# MCU_NAVSS0_UDMASS_UDMAP_TCHANRT register map
Vendor: Texas Instruments
Peripheral module from a debugger description file (folder am65x).
Registers are 32-bit, read-write, reset 0x0 unless marked. A register's access mark holds for its fields unless they carry their own. Offsets are as the file gives them; lines under a group give offsets from that group; [hi:lo] are bit positions; {n}, {i} and the like mark numbered series; 'fields as' and 'values as' point back to an identical list; <NAME> marks a mode.

## MCU_NAVSS0_UDMASS_UDMAP_TCHANRT
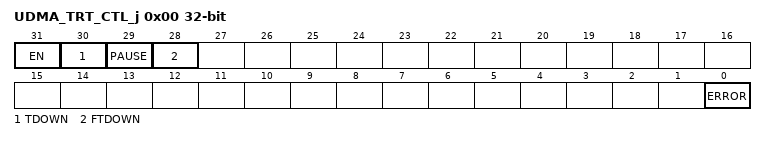
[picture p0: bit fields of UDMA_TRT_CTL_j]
0x00 UDMA_TRT_CTL_j access per field — The Tx Channel Realtime Control Register contains real-time control and status information for the Tx DMA channel. The fields in this register can safely be changed while the channel is in operation. Offset = 0h + (j * 1000h); where j = 0h to 97h for NAVSS0_UDMASS_UDMAP0_CFG_TCHANRT j = 0h to 2Fh for MCU_NAVSS0_UDMASS_UDMAP_TCHANRT
  [31] EN rw — This field enables or disables the channel. Disabling a channel halts operation on the channel after the current block transfer is completed. Disabling a channel in the middle of a packet transfer may result in underflow conditions in the attached application block and data loss. When a channel is disabled, the implementation may choose to reset all state for the channel. The pause bit should be asserted instead of clearing enable directly if the intent is to temporarily pause the channel. This field is encoded as follows: 0 = channel is disabled 1 = channel is enabled This field will be cleared by HW after a teardown is requested to indicate that the channel teardown is complete.
  [30] TDOWN rw — Channel teardown: Setting this bit will request the channel to be torn down. This field will remain set after a channel teardown is complete.
  [29] PAUSE rw — Channel pause: Setting this bit will cause the channel to pause processing immediately.
  [28] FTDOWN rw — Channel forced teardown: Setting this bit will cause the channel to stop waiting on trigger events. When this bit is set, the implementation may choose to bypass data transfers and event generation. This bit is a modifier to the normal tx_teardown and is intended to flush the channel to recover any descriptor or TR references which are currently being held by the UDMA-P even if the trigger source is no longer functioning. Uso fo this bit is considered a 'catastrophic' condition and it is assumed that SW will need to perform some re-initialization in the system to re-align events, data buffers, etc. This bit should be set in addition to the tx_teardown bit in order to cause a forced teardown. This field will remain set after a channel teardown is complete.
  [0] ERROR ro — Channel error: This bit will be set anytime an error has occurred on the channel. This bit is cleared when the channel is disabled and re-enabled.
0x08 UDMA_TRT_SWTRIG_j wo — The Software Trigger Register provides a mechanism by which software can directly trigger the channel in a secure way. This register is only used when the tx_chan_type is configured as a Third Party DMA channel. This register has no function when the channel is configured for packet mode transfers. A write to this register will cause an event to be sent to this channel. Offset = 8h + (j * 1000h); where j = 0h to 97h for NAVSS0_UDMASS_UDMAP0_CFG_TCHANRT j = 0h to 2Fh for MCU_NAVSS0_UDMASS_UDMAP_TCHANRT
  [0] TRIGGER — Trigger: writing this bit with a value of 1 will cause the trigger event to be sent to this channel
0x80 UDMA_TRT_STDATA_j_Y ro — The State Data Registers contain the current working state of the Tx DMA channel. These registers are provided so that the Host can determine the potential cause of an error or exception condition which was reported by the channel. These registers should not be accessed without reason while the UDMA-P is operating as accesses will cause performance to decrease as these MMRs are just providing a window into the actual state RAM Offset = 80h + (j * 1000h) + (y * 4h); where j = 0h to 97h, y = 0h to 1Fh for NAVSS0_UDMASS_UDMAP0_CFG_TCHANRT j = 0h to 2Fh, y = 0h to 1Fh for MCU_NAVSS0_UDMASS_UDMAP_TCHANRT
  [31:0] STATE_INFO — See Tx state mapping table
{0x200+4i} UDMA_TRT_PEER{i}_j (i=0..2) — This register provides access to the remote peer's realtime register at {0x400+i}. Offset = {4i+200}h + (j * 1000h); where j = 0h to 97h for NAVSS0_UDMASS_UDMAP0_CFG_TCHANRT j = 0h to 2Fh for MCU_NAVSS0_UDMASS_UDMAP_TCHANRT
  [31:0] PEER_DATA — Peer realtime register data (varies by paired peer).
0x20C UDMA_TRT_PEER3_j — This register provides access to the remote peer's realtime register at 0x403. Offset = 20Ch + (j * 1000h); where j = 0h to 97h for NAVSS0_UDMASS_UDMAP0_CFG_TCHANRT j = 0h to 2Fh for MCU_NAVSS0_UDMASS_UDMAP_TCHANRT
  fields as UDMA_TRT_PEER0_j
{0x200+4i} UDMA_TRT_PEER{i}_j (i=4..6) — This register provides access to the remote peer's realtime register at {0x400+i}. Offset = {4i+194}h + (j * 1000h); where j = 0h to 97h for NAVSS0_UDMASS_UDMAP0_CFG_TCHANRT j = 0h to 2Fh for MCU_NAVSS0_UDMASS_UDMAP_TCHANRT
  fields as UDMA_TRT_PEER0_j
0x21C UDMA_TRT_PEER7_j — This register provides access to the remote peer's realtime register at 0x407. Offset = 21Ch + (j * 1000h); where j = 0h to 97h for NAVSS0_UDMASS_UDMAP0_CFG_TCHANRT j = 0h to 2Fh for MCU_NAVSS0_UDMASS_UDMAP_TCHANRT
  fields as UDMA_TRT_PEER0_j
{0x200+4i} UDMA_TRT_PEER{i}_j (i=8..10) — This register provides access to the remote peer's realtime register at {0x400+i}. Offset = {4i+188}h + (j * 1000h); where j = 0h to 97h for NAVSS0_UDMASS_UDMAP0_CFG_TCHANRT j = 0h to 2Fh for MCU_NAVSS0_UDMASS_UDMAP_TCHANRT
  fields as UDMA_TRT_PEER0_j
0x22C UDMA_TRT_PEER11_j — This register provides access to the remote peer's realtime register at 0x40B. Offset = 22Ch + (j * 1000h); where j = 0h to 97h for NAVSS0_UDMASS_UDMAP0_CFG_TCHANRT j = 0h to 2Fh for MCU_NAVSS0_UDMASS_UDMAP_TCHANRT
  fields as UDMA_TRT_PEER0_j
{0x200+4i} UDMA_TRT_PEER{i}_j (i=12..14) — This register provides access to the remote peer's realtime register at {0x400+i}. Offset = {4i+182}h + (j * 1000h); where j = 0h to 97h for NAVSS0_UDMASS_UDMAP0_CFG_TCHANRT j = 0h to 2Fh for MCU_NAVSS0_UDMASS_UDMAP_TCHANRT
  fields as UDMA_TRT_PEER0_j
0x23C UDMA_TRT_PEER15_j — This register provides access to the remote peer's realtime register at 0x40F. Offset = 23Ch + (j * 1000h); where j = 0h to 97h for NAVSS0_UDMASS_UDMAP0_CFG_TCHANRT j = 0h to 2Fh for MCU_NAVSS0_UDMASS_UDMAP_TCHANRT
  fields as UDMA_TRT_PEER0_j
0x400 UDMA_TRT_PCNT_j — The statistics registers are supplied to give software applications operational progress status for the channel. Offset = 400h + (j * 1000h); where j = 0h to 97h for NAVSS0_UDMASS_UDMAP0_CFG_TCHANRT j = 0h to 2Fh for MCU_NAVSS0_UDMASS_UDMAP_TCHANRT
  [31:0] PCNT — Current completed packet count for the channel.
0x408 UDMA_TRT_BCNT_j — The statistics registers are supplied to give software applications operational progress status for the channel. Offset = 408h + (j * 1000h); where j = 0h to 97h for NAVSS0_UDMASS_UDMAP0_CFG_TCHANRT j = 0h to 2Fh for MCU_NAVSS0_UDMASS_UDMAP_TCHANRT
  [31:0] BCNT — Current completed payload byte count for the channel.
0x410 UDMA_TRT_SBCNT_j — The statistics registers are supplied to give software applications operational progress status for the channel. Offset = 410h + (j * 1000h); where j = 0h to 97h for NAVSS0_UDMASS_UDMAP0_CFG_TCHANRT j = 0h to 2Fh for MCU_NAVSS0_UDMASS_UDMAP_TCHANRT
  [31:0] SBCNT — Current started byte count for the channel.
